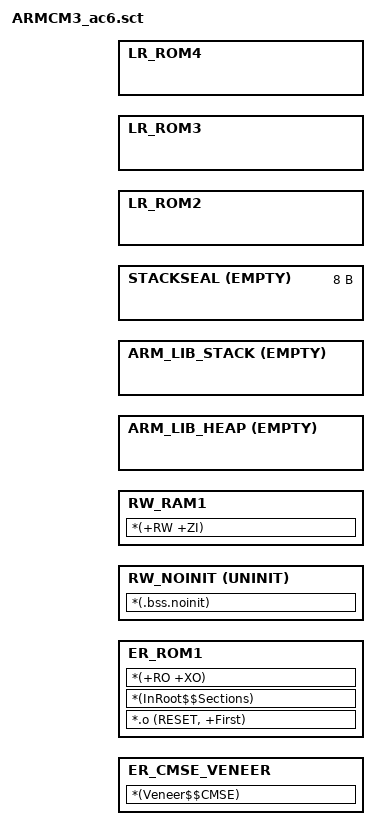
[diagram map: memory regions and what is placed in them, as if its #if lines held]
/* ----------------------------------------------------------------------------
  Stack seal size definition
 *----------------------------------------------------------------------------*/
#if defined (__ARM_FEATURE_CMSE) && (__ARM_FEATURE_CMSE == 3U)
#define __STACKSEAL_SIZE   ( 8 )
#else
#define __STACKSEAL_SIZE   ( 0 )
#endif

/*----------------------------------------------------------------------------
  Scatter File Definitions definition
 *----------------------------------------------------------------------------*/

LR_ROM1 __ROM1_BASE __ROM1_SIZE  {

#if defined (__ARM_FEATURE_CMSE) && (__ARM_FEATURE_CMSE == 3U)
  ER_CMSE_VENEER __ROM1_BASE+__ROM1_SIZE -__ROM1_SIZE {
   *(Veneer$$CMSE)
  }
#endif

  ER_ROM1 __ROM1_BASE (__ROM1_SIZE - AlignExpr(ImageLength(ER_CMSE_VENEER), 8)) {
   *.o (RESET, +First)
   *(InRoot$$Sections)
   *(+RO +XO)
  }

  RW_NOINIT __RAM1_BASE UNINIT (__RAM1_SIZE - __HEAP_SIZE - __STACK_SIZE) {
    *(.bss.noinit)
  }

  RW_RAM1 AlignExpr(+0, 8) (__RAM1_SIZE - __HEAP_SIZE - __STACK_SIZE - AlignExpr(ImageLength(RW_NOINIT), 8)) {
    *(+RW +ZI)
  }

#if __HEAP_SIZE > 0
  ARM_LIB_HEAP  (AlignExpr(+0, 8)) EMPTY __HEAP_SIZE  {   ; Reserve empty region for heap
  }
#endif

  ARM_LIB_STACK (__RAM1_BASE + __RAM1_SIZE - __STACKSEAL_SIZE) EMPTY -__STACK_SIZE {   ; Reserve empty region for stack
  }

#if __STACKSEAL_SIZE > 0
  STACKSEAL +0 EMPTY 8 {             ; Reserve empty region for stack seal immediately after stack
  }
#endif

#if __RAM2_SIZE > 0
  RW_RAM2 __RAM2_BASE __RAM2_SIZE
   .ANY (+RW +ZI)
  }
#endif

#if __RAM3_SIZE > 0
  RW_RAM3 __RAM3_BASE __RAM3_SIZE  {
   .ANY (+RW +ZI)
  }
#endif

#if __RAM4_SIZE > 0
  RW_RAM4 __RAM4_BASE __RAM4_SIZE  {
   .ANY (+RW +ZI)
  }
#endif
}

#if __ROM2_SIZE > 0
LR_ROM2 __ROM2_BASE __ROM2_SIZE  {
  ER_ROM2 +0 __ROM2_SIZE {
   .ANY (+RO +XO)
  }
}
#endif

#if __ROM3_SIZE > 0
LR_ROM3 __ROM3_BASE __ROM3_SIZE  {
  ER_ROM3 +0 __ROM3_SIZE {
   .ANY (+RO +XO)
  }
}
#endif

#if __ROM4_SIZE > 0
LR_ROM4 __ROM4_BASE __ROM4_SIZE  {
  ER_ROM4 +0 __ROM4_SIZE {
   .ANY (+RO +XO)
  }
}
#endif
